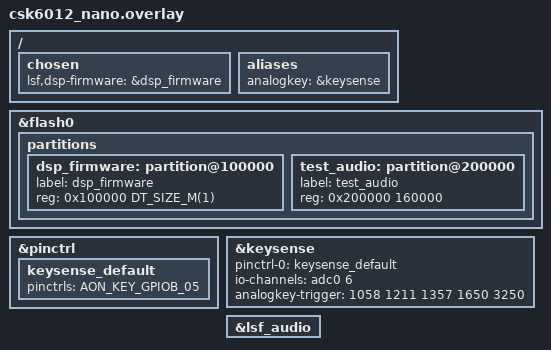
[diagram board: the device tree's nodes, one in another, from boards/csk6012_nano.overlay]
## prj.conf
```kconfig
CONFIG_HEAP_MEM_POOL_SIZE=204800

CONFIG_CSK_HEAP=y
CONFIG_CSK_HEAP_MEM_POOL_SIZE=40960

CONFIG_CSK6_FLASH_STALL_SECOND_CORE=n

CONFIG_GPIO=y

CONFIG_ADC=y

CONFIG_KSCAN=y
CONFIG_KSCAN_CSK6=y
```

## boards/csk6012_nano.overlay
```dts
/*
 * Copyright(c) 2023 LISTENAI
 * SPDX-License-Identifier: Apache-2.0
 */

#include <lsf/lsf.dtsi>

/ {
	chosen {
		lsf,dsp-firmware = &dsp_firmware;
	};

	aliases {
		analogkey = &keysense;
	};
};

&flash0 {
	partitions {
		dsp_firmware: partition@100000 {
			label = "dsp_firmware";
			reg = <0x100000 DT_SIZE_M(1)>;
		};

		test_audio: partition@200000 {
			label = "test_audio";
			reg = <0x200000 160000>;
		};
	};
};

&pinctrl {
	keysense_default: keysense_default {
		pinctrls = <AON_KEY_GPIOB_05>;
	};
};

&keysense {
	status = "okay";
	pinctrl-0 = <&keysense_default>;
	pinctrl-names = "default";
	io-channels = <&adc0 6>;
	analogkey-trigger = <
		1058 /* K4 */
		1211 /* K3 */
		1357 /* K2 */
		1650 /* K1 */
		3250 /* SW2 */
	>;
};

&lsf_audio {
	status = "okay";
};
```

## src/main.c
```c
/*
 * Copyright(c) 2023 LISTENAI
 * SPDX-License-Identifier: Apache-2.0
 */

#include <assert.h>

#include <zephyr/kernel.h>
#include <zephyr/device.h>
#include <zephyr/storage/flash_map.h>
#include <zephyr/drivers/gpio.h>
#include <zephyr/drivers/kscan.h>
#include <zephyr/sys/util.h>

#include "AudioSystem.h"
#include "AudioTrack.h"

#define SAMPLE_RATE (16000)
#define CHANNEL_CNT (1)

#define FLASH_ADDR      (DT_REG_ADDR(DT_CHOSEN(zephyr_flash)))
#define TEST_AUDIO_ADDR (FLASH_ADDR + FLASH_AREA_OFFSET(test_audio))
#define TEST_AUDIO_SIZE (FLASH_AREA_SIZE(test_audio))

enum csk_adc_key_t {
	KEY_K4,
	KEY_K3,
	KEY_K2,
	KEY_K1,
	KEY_SW2,
};

static const struct device *kscan = DEVICE_DT_GET(DT_ALIAS(analogkey));
static const struct gpio_dt_spec led = GPIO_DT_SPEC_GET(DT_ALIAS(led0), gpios);

static AudioTrack s_track_obj;

static struct k_sem s_sem_start;
static volatile bool s_busy;

static void kscan_callback(const struct device *dev, uint32_t row, uint32_t column, bool pressed)
{
	if (!pressed) {
		return;
	}

	printk("Key %d pressed at %" PRIu32 "\n", row, k_cycle_get_32());

	switch (row) {
	case KEY_SW2:
		if (!s_busy) {
			k_sem_give(&s_sem_start);
		}
		break;
	case KEY_K1:
		AudioTrack_stop(&s_track_obj);
		break;
	case KEY_K2: {
		bool muted = AudioTrack_muted(&s_track_obj);
		AudioTrack_mute(&s_track_obj, !muted);
		printk("Muted: %d\n", !muted);
	} break;
	case KEY_K3: {
		float left, right;
		AudioTrack_getVolume(&s_track_obj, &left, &right);
		left = MAX(0.0f, left - 0.1f);
		right = MAX(0.0f, right - 0.1f);
		AudioTrack_setVolume(&s_track_obj, left, right);
		printk("Volume: %.2f %.2f\n", left, right);
	} break;
	case KEY_K4: {
		float left, right;
		AudioTrack_getVolume(&s_track_obj, &left, &right);
		left = MIN(1.0f, left + 0.1f);
		right = MIN(1.0f, right + 0.1f);
		AudioTrack_setVolume(&s_track_obj, left, right);
		printk("Volume: %.2f %.2f\n", left, right);
	} break;
	}
}

void main(void)
{
	int ret;
	ssize_t wrote;

	printk("Hello World! %s\n", CONFIG_BOARD);

	k_sem_init(&s_sem_start, 0, 1);

	/* 初始化 GPIO */
	ret = kscan_config(kscan, kscan_callback);
	assert(0 == ret);

	ret = gpio_pin_configure_dt(&led, GPIO_OUTPUT_INACTIVE);
	assert(0 == ret);

	/* 初始化音频组件 */
	AudioTrack *track = &s_track_obj;
	ret = AudioTrack_ctor(track, SAMPLE_RATE, PCM_16_BIT, CHANNEL_OUT_MONO, 0, NULL);
	assert(0 == ret);

	while (1) {
		printk("SW2=PLAY, K1=STOP, K2=MUTE/UNMUTE, K3=VOL-, K4=VOL+\n");
		printk("Press SW2 to play\n");

		/* 循环等待按键按下 */
		k_sem_take(&s_sem_start, K_FOREVER);
		s_busy = true;

		gpio_pin_set_dt(&led, 1);

		AudioTrack_start(track);

		wrote = AudioTrack_write(track, (const void *)TEST_AUDIO_ADDR, TEST_AUDIO_SIZE);
		printk("Actual wrote %d of %d bytes\n", wrote, TEST_AUDIO_SIZE);

		AudioTrack_stop(track);

		gpio_pin_set_dt(&led, 0);

		s_busy = false;
	}
}
```
